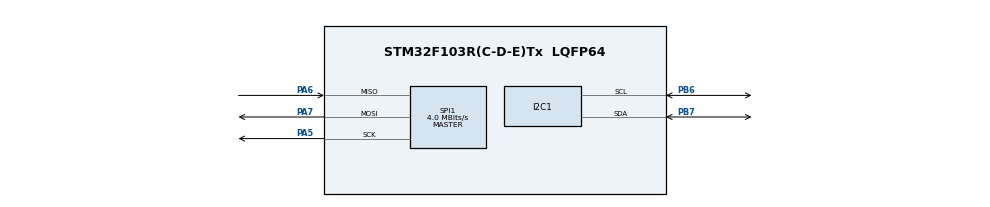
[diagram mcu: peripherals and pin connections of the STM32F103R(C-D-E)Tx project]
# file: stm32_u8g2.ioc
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Mcu.Family=STM32F1
Mcu.Name=STM32F103R(C-D-E)Tx
Mcu.Package=LQFP64
NVIC.PriorityGroup=NVIC_PRIORITYGROUP_4
PA5.Mode=Full_Duplex_Master
PA5.Signal=SPI1_SCK
PA6.Mode=Full_Duplex_Master
PA6.Signal=SPI1_MISO
PA7.Mode=Full_Duplex_Master
PA7.Signal=SPI1_MOSI
PB6.Mode=I2C
PB6.Signal=I2C1_SCL
PB7.Mode=I2C
PB7.Signal=I2C1_SDA
ProjectManager.HeapSize=0x200
ProjectManager.StackSize=0x400
ProjectManager.TargetToolchain=STM32CubeIDE
RCC.APB1Freq_Value=8000000
RCC.APB2Freq_Value=8000000
SPI1.CalculateBaudRate=4.0 MBits/s
SPI1.Direction=SPI_DIRECTION_2LINES
SPI1.Mode=SPI_MODE_MASTER
SPI1.VirtualType=VM_MASTER
VP_SYS_VS_ND.Mode=No_Debug
board=custom

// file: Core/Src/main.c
/* USER CODE BEGIN Header */
/**
  ******************************************************************************
  * @file           : main.c
  * @brief          : Main program body
  ******************************************************************************
  * @attention
  *
  * Copyright (c) 2025 STMicroelectronics.
  * All rights reserved.
  *
  * This software is licensed under terms that can be found in the LICENSE file
  * in the root directory of this software component.
  * If no LICENSE file comes with this software, it is provided AS-IS.
  *
  ******************************************************************************
  */
/* USER CODE END Header */
#include "main.h"
#include "i2c.h"
#include "spi.h"
#include "gpio.h"

/* USER CODE BEGIN Includes */
#include "u8g2.h"
#include "u8g2_user_port.h"
/* USER CODE END Includes */

/* USER CODE BEGIN PM */
u8g2_t  u8g2;
/* USER CODE END PM */

void SystemClock_Config(void);

int main(void)
{

  /* MCU Configuration--------------------------------------------------------*/

  /* Reset of all peripherals, Initializes the Flash interface and the Systick. */
  HAL_Init();

  /* Configure the system clock */
  SystemClock_Config();

  /* Initialize all configured peripherals */
  MX_GPIO_Init();
  MX_I2C1_Init();
  MX_SPI1_Init();
  /* USER CODE BEGIN 2 */
  U8G2_Init(&u8g2);

  u8g2_SetFont(&u8g2,u8g2_font_timB08_tr);
  u8g2_DrawUTF8(&u8g2,0,0,"Hello World");
  u8g2_SendBuffer(&u8g2);
  /* USER CODE END 2 */

  /* Infinite loop */
  while (1)
  {

  }
}

void SystemClock_Config(void)
{
  RCC_OscInitTypeDef RCC_OscInitStruct = {0};
  RCC_ClkInitTypeDef RCC_ClkInitStruct = {0};

  /** Initializes the RCC Oscillators according to the specified parameters
  * in the RCC_OscInitTypeDef structure.
  */
  RCC_OscInitStruct.OscillatorType = RCC_OSCILLATORTYPE_HSI;
  RCC_OscInitStruct.HSIState = RCC_HSI_ON;
  RCC_OscInitStruct.HSICalibrationValue = RCC_HSICALIBRATION_DEFAULT;
  RCC_OscInitStruct.PLL.PLLState = RCC_PLL_NONE;
  if (HAL_RCC_OscConfig(&RCC_OscInitStruct) != HAL_OK)
  {
    Error_Handler();
  }

  /** Initializes the CPU, AHB and APB buses clocks
  */
  RCC_ClkInitStruct.ClockType = RCC_CLOCKTYPE_HCLK|RCC_CLOCKTYPE_SYSCLK
                              |RCC_CLOCKTYPE_PCLK1|RCC_CLOCKTYPE_PCLK2;
  RCC_ClkInitStruct.SYSCLKSource = RCC_SYSCLKSOURCE_HSI;
  RCC_ClkInitStruct.AHBCLKDivider = RCC_SYSCLK_DIV1;
  RCC_ClkInitStruct.APB1CLKDivider = RCC_HCLK_DIV1;
  RCC_ClkInitStruct.APB2CLKDivider = RCC_HCLK_DIV1;

  if (HAL_RCC_ClockConfig(&RCC_ClkInitStruct, FLASH_LATENCY_0) != HAL_OK)
  {
    Error_Handler();
  }
}

void Error_Handler(void)
{
  __disable_irq();
  while (1)
  {
  }
}
